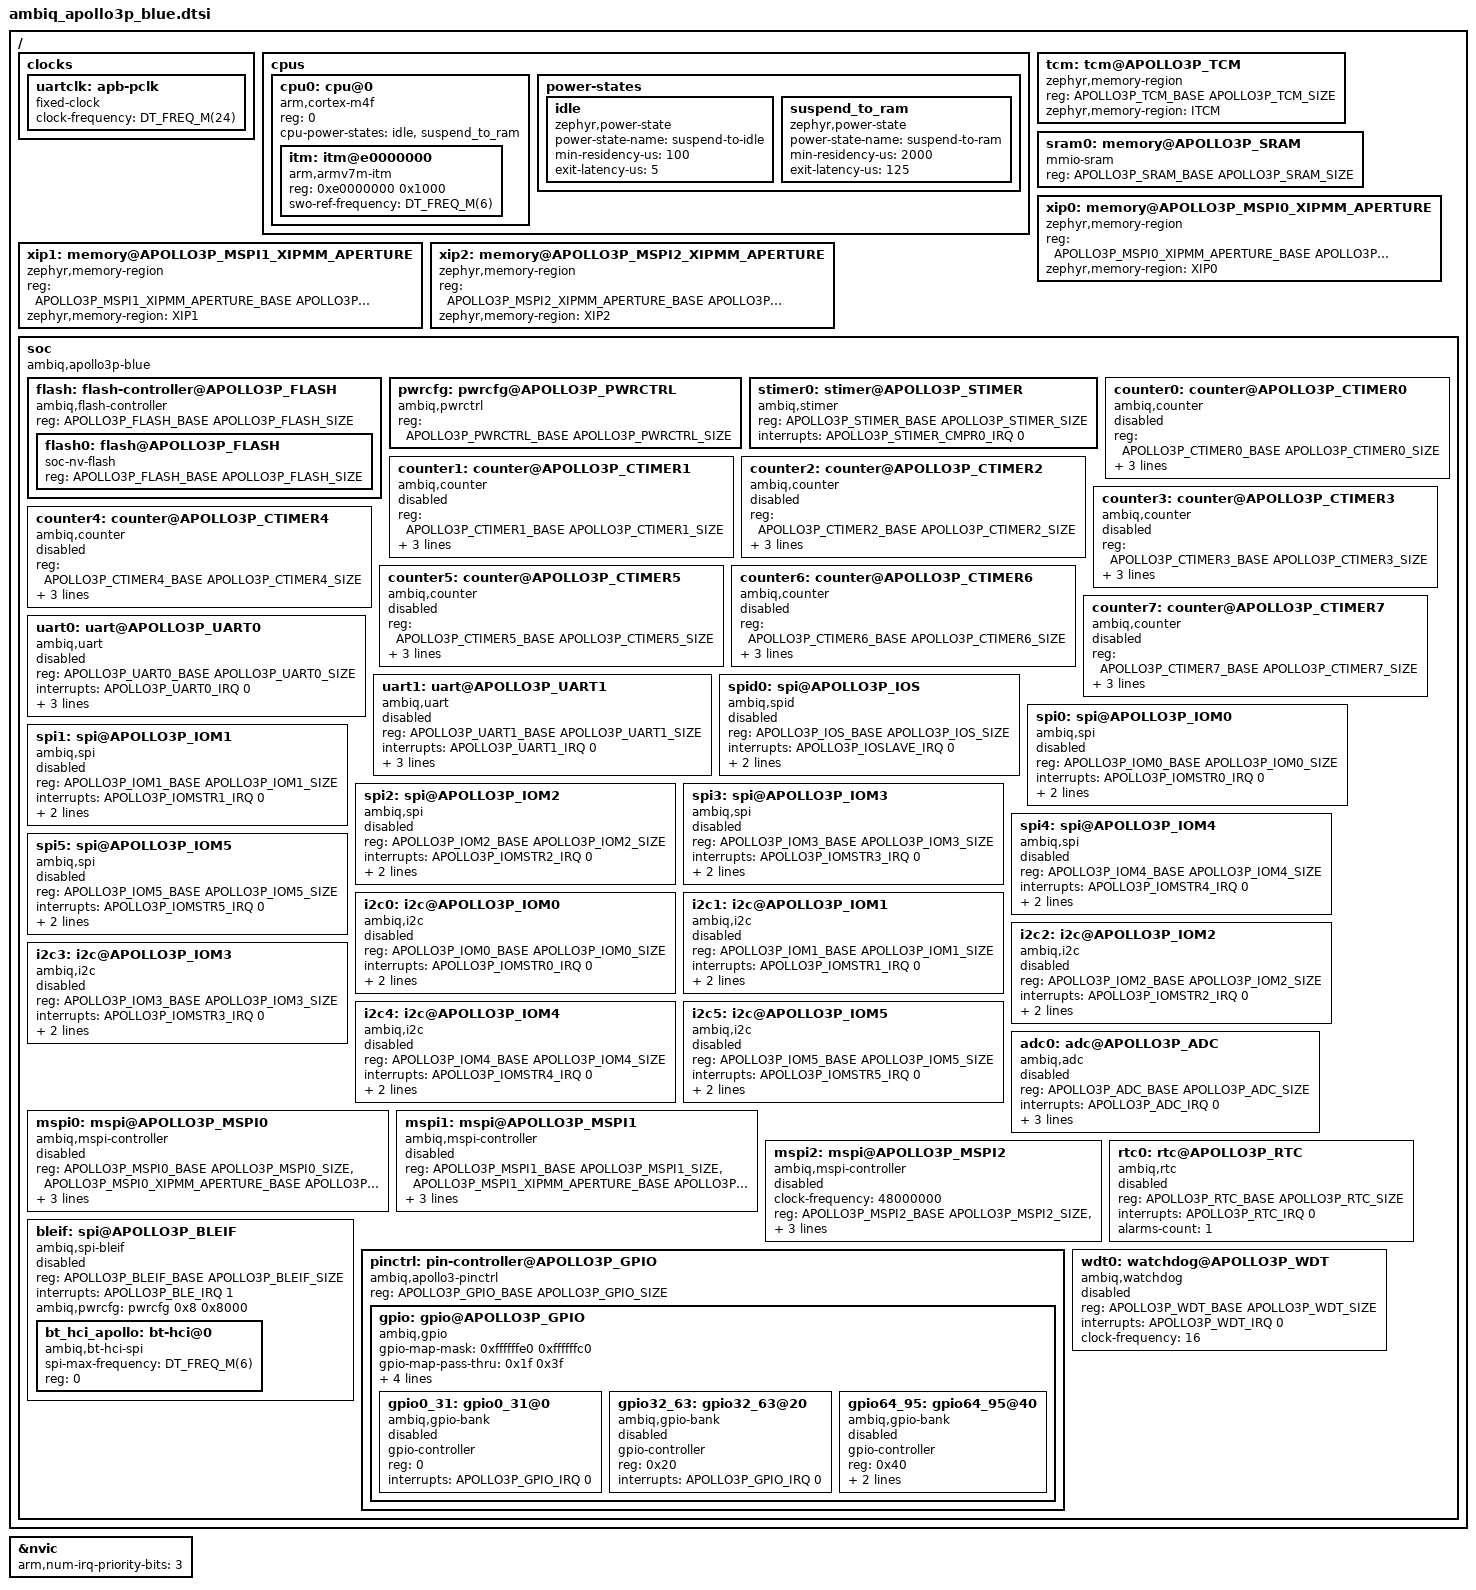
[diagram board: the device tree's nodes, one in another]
/* SPDX-License-Identifier: Apache-2.0 */

#include <arm/armv7-m.dtsi>
#include <mem.h>
#include <freq.h>
#include <apollo3p/am_apollo3p.h>
#include <zephyr/dt-bindings/adc/adc.h>
#include <zephyr/dt-bindings/i2c/i2c.h>
#include <zephyr/dt-bindings/gpio/gpio.h>

/ {
	clocks {
		uartclk: apb-pclk {
			compatible = "fixed-clock";
			clock-frequency = <DT_FREQ_M(24)>;
			#clock-cells = <0>;
		};
	};

	cpus {
		#address-cells = <1>;
		#size-cells = <0>;

		cpu0: cpu@0 {
			compatible = "arm,cortex-m4f";
			reg = <0>;
			cpu-power-states = <&idle &suspend_to_ram>;
			#address-cells = <1>;
			#size-cells = <1>;

			itm: itm@e0000000 {
				compatible = "arm,armv7m-itm";
				reg = <0xe0000000 0x1000>;
				swo-ref-frequency = <DT_FREQ_M(6)>;
			};
		};

		power-states {
			idle: idle {
				compatible = "zephyr,power-state";
				power-state-name = "suspend-to-idle";
				/* As Apollo3blueplus datasheet, run_to_sleep and sleep_to_run
				 * transition time are both lower than 1us, but considering
				 * the software overhead we set a bigger value.
				 */
				min-residency-us = <100>;
				exit-latency-us = <5>;
			};

			suspend_to_ram: suspend_to_ram {
				compatible = "zephyr,power-state";
				power-state-name = "suspend-to-ram";
				/* As Apollo3blueplus datasheet, run_to_deepsleep transition time
				 * is the software overhead 1us and deepsleep_to_run transition
				 * time is about 25us,but considering the software overhead,
				 * we set a bigger value.
				 */
				min-residency-us = <2000>;
				exit-latency-us = <125>;
			};
		};
	};

	/* TCM */
	tcm: tcm@APOLLO3P_TCM {
		compatible = "zephyr,memory-region";
		reg = <APOLLO3P_TCM_BASE APOLLO3P_TCM_SIZE>;
		zephyr,memory-region = "ITCM";
	};

	/* SRAM */
	sram0: memory@APOLLO3P_SRAM {
		compatible = "mmio-sram";
		reg = <APOLLO3P_SRAM_BASE APOLLO3P_SRAM_SIZE>;
	};

	xip0: memory@APOLLO3P_MSPI0_XIPMM_APERTURE {
		compatible = "zephyr,memory-region";
		reg = <APOLLO3P_MSPI0_XIPMM_APERTURE_BASE APOLLO3P_MSPI0_XIPMM_APERTURE_SIZE>;
		zephyr,memory-region = "XIP0";
	};

	xip1: memory@APOLLO3P_MSPI1_XIPMM_APERTURE {
		compatible = "zephyr,memory-region";
		reg = <APOLLO3P_MSPI1_XIPMM_APERTURE_BASE APOLLO3P_MSPI1_XIPMM_APERTURE_SIZE>;
		zephyr,memory-region = "XIP1";
	};

	xip2: memory@APOLLO3P_MSPI2_XIPMM_APERTURE {
		compatible = "zephyr,memory-region";
		reg = <APOLLO3P_MSPI2_XIPMM_APERTURE_BASE APOLLO3P_MSPI2_XIPMM_APERTURE_SIZE>;
		zephyr,memory-region = "XIP2";
	};

	soc {
		compatible = "ambiq,apollo3p-blue", "ambiq,apollo3x", "simple-bus";

		flash: flash-controller@APOLLO3P_FLASH {
			compatible = "ambiq,flash-controller";
			reg = <APOLLO3P_FLASH_BASE APOLLO3P_FLASH_SIZE>;

			#address-cells = <1>;
			#size-cells = <1>;

			/* Flash region */
			flash0: flash@APOLLO3P_FLASH {
				compatible = "soc-nv-flash";
				reg = <APOLLO3P_FLASH_BASE APOLLO3P_FLASH_SIZE>;
			};
		};

		pwrcfg: pwrcfg@APOLLO3P_PWRCTRL {
			compatible = "ambiq,pwrctrl";
			reg = <APOLLO3P_PWRCTRL_BASE APOLLO3P_PWRCTRL_SIZE>;
			#pwrcfg-cells = <2>;
		};

		stimer0: stimer@APOLLO3P_STIMER {
			compatible = "ambiq,stimer";
			reg = <APOLLO3P_STIMER_BASE APOLLO3P_STIMER_SIZE>;
			interrupts = <APOLLO3P_STIMER_CMPR0_IRQ 0>;
			status = "okay";
		};

		counter0: counter@APOLLO3P_CTIMER0 {
			compatible = "ambiq,counter";
			reg = <APOLLO3P_CTIMER0_BASE APOLLO3P_CTIMER0_SIZE>;
			interrupts = <APOLLO3P_CTIMER_IRQ 0>;
			clock-frequency = <DT_FREQ_M(3)>;
			clk-source = <2>;
			status = "disabled";
		};

		counter1: counter@APOLLO3P_CTIMER1 {
			compatible = "ambiq,counter";
			reg = <APOLLO3P_CTIMER1_BASE APOLLO3P_CTIMER1_SIZE>;
			interrupts = <APOLLO3P_CTIMER_IRQ 0>;
			clock-frequency = <DT_FREQ_M(3)>;
			clk-source = <2>;
			status = "disabled";
		};

		counter2: counter@APOLLO3P_CTIMER2 {
			compatible = "ambiq,counter";
			reg = <APOLLO3P_CTIMER2_BASE APOLLO3P_CTIMER2_SIZE>;
			interrupts = <APOLLO3P_CTIMER_IRQ 0>;
			clock-frequency = <DT_FREQ_M(3)>;
			clk-source = <2>;
			status = "disabled";
		};

		counter3: counter@APOLLO3P_CTIMER3 {
			compatible = "ambiq,counter";
			reg = <APOLLO3P_CTIMER3_BASE APOLLO3P_CTIMER3_SIZE>;
			interrupts = <APOLLO3P_CTIMER_IRQ 0>;
			clock-frequency = <DT_FREQ_M(3)>;
			clk-source = <2>;
			status = "disabled";
		};

		counter4: counter@APOLLO3P_CTIMER4 {
			compatible = "ambiq,counter";
			reg = <APOLLO3P_CTIMER4_BASE APOLLO3P_CTIMER4_SIZE>;
			interrupts = <APOLLO3P_CTIMER_IRQ 0>;
			clock-frequency = <DT_FREQ_M(3)>;
			clk-source = <2>;
			status = "disabled";
		};

		counter5: counter@APOLLO3P_CTIMER5 {
			compatible = "ambiq,counter";
			reg = <APOLLO3P_CTIMER5_BASE APOLLO3P_CTIMER5_SIZE>;
			interrupts = <APOLLO3P_CTIMER_IRQ 0>;
			clock-frequency = <DT_FREQ_M(3)>;
			clk-source = <2>;
			status = "disabled";
		};

		counter6: counter@APOLLO3P_CTIMER6 {
			compatible = "ambiq,counter";
			reg = <APOLLO3P_CTIMER6_BASE APOLLO3P_CTIMER6_SIZE>;
			interrupts = <APOLLO3P_CTIMER_IRQ 0>;
			clock-frequency = <DT_FREQ_M(3)>;
			clk-source = <2>;
			status = "disabled";
		};

		counter7: counter@APOLLO3P_CTIMER7 {
			compatible = "ambiq,counter";
			reg = <APOLLO3P_CTIMER7_BASE APOLLO3P_CTIMER7_SIZE>;
			interrupts = <APOLLO3P_CTIMER_IRQ 0>;
			clock-frequency = <DT_FREQ_M(3)>;
			clk-source = <2>;
			status = "disabled";
		};

		uart0: uart@APOLLO3P_UART0 {
			compatible = "ambiq,uart", "arm,pl011";
			reg = <APOLLO3P_UART0_BASE APOLLO3P_UART0_SIZE>;
			interrupts = <APOLLO3P_UART0_IRQ 0>;
			interrupt-names = "UART0";
			status = "disabled";
			clocks = <&uartclk>;
			ambiq,pwrcfg = <&pwrcfg 0x8 0x80>;
			zephyr,pm-device-runtime-auto;
		};

		uart1: uart@APOLLO3P_UART1 {
			compatible = "ambiq,uart", "arm,pl011";
			reg = <APOLLO3P_UART1_BASE APOLLO3P_UART1_SIZE>;
			interrupts = <APOLLO3P_UART1_IRQ 0>;
			interrupt-names = "UART1";
			status = "disabled";
			clocks = <&uartclk>;
			ambiq,pwrcfg = <&pwrcfg 0x8 0x100>;
			zephyr,pm-device-runtime-auto;
		};

		spid0: spi@APOLLO3P_IOS {
			compatible = "ambiq,spid";
			reg = <APOLLO3P_IOS_BASE APOLLO3P_IOS_SIZE>;
			#address-cells = <1>;
			#size-cells = <0>;
			interrupts = <APOLLO3P_IOSLAVE_IRQ 0>;
			status = "disabled";
			ambiq,pwrcfg = <&pwrcfg 0x8 0>;
			zephyr,pm-device-runtime-auto;
		};

		spi0: spi@APOLLO3P_IOM0 {
			compatible = "ambiq,spi";
			reg = <APOLLO3P_IOM0_BASE APOLLO3P_IOM0_SIZE>;
			#address-cells = <1>;
			#size-cells = <0>;
			interrupts = <APOLLO3P_IOMSTR0_IRQ 0>;
			status = "disabled";
			ambiq,pwrcfg = <&pwrcfg 0x8 0x2>;
			zephyr,pm-device-runtime-auto;
		};

		spi1: spi@APOLLO3P_IOM1 {
			compatible = "ambiq,spi";
			reg = <APOLLO3P_IOM1_BASE APOLLO3P_IOM1_SIZE>;
			#address-cells = <1>;
			#size-cells = <0>;
			interrupts = <APOLLO3P_IOMSTR1_IRQ 0>;
			status = "disabled";
			ambiq,pwrcfg = <&pwrcfg 0x8 0x4>;
			zephyr,pm-device-runtime-auto;
		};

		spi2: spi@APOLLO3P_IOM2 {
			compatible = "ambiq,spi";
			reg = <APOLLO3P_IOM2_BASE APOLLO3P_IOM2_SIZE>;
			#address-cells = <1>;
			#size-cells = <0>;
			interrupts = <APOLLO3P_IOMSTR2_IRQ 0>;
			status = "disabled";
			ambiq,pwrcfg = <&pwrcfg 0x8 0x8>;
			zephyr,pm-device-runtime-auto;
		};

		spi3: spi@APOLLO3P_IOM3 {
			compatible = "ambiq,spi";
			reg = <APOLLO3P_IOM3_BASE APOLLO3P_IOM3_SIZE>;
			#address-cells = <1>;
			#size-cells = <0>;
			interrupts = <APOLLO3P_IOMSTR3_IRQ 0>;
			status = "disabled";
			ambiq,pwrcfg = <&pwrcfg 0x8 0x10>;
			zephyr,pm-device-runtime-auto;
		};

		spi4: spi@APOLLO3P_IOM4 {
			compatible = "ambiq,spi";
			reg = <APOLLO3P_IOM4_BASE APOLLO3P_IOM4_SIZE>;
			#address-cells = <1>;
			#size-cells = <0>;
			interrupts = <APOLLO3P_IOMSTR4_IRQ 0>;
			status = "disabled";
			ambiq,pwrcfg = <&pwrcfg 0x8 0x20>;
			zephyr,pm-device-runtime-auto;
		};

		spi5: spi@APOLLO3P_IOM5 {
			compatible = "ambiq,spi";
			reg = <APOLLO3P_IOM5_BASE APOLLO3P_IOM5_SIZE>;
			#address-cells = <1>;
			#size-cells = <0>;
			interrupts = <APOLLO3P_IOMSTR5_IRQ 0>;
			status = "disabled";
			ambiq,pwrcfg = <&pwrcfg 0x8 0x40>;
			zephyr,pm-device-runtime-auto;
		};

		i2c0: i2c@APOLLO3P_IOM0 {
			compatible = "ambiq,i2c";
			reg = <APOLLO3P_IOM0_BASE APOLLO3P_IOM0_SIZE>;
			#address-cells = <1>;
			#size-cells = <0>;
			interrupts = <APOLLO3P_IOMSTR0_IRQ 0>;
			status = "disabled";
			ambiq,pwrcfg = <&pwrcfg 0x8 0x2>;
			zephyr,pm-device-runtime-auto;
		};

		i2c1: i2c@APOLLO3P_IOM1 {
			compatible = "ambiq,i2c";
			reg = <APOLLO3P_IOM1_BASE APOLLO3P_IOM1_SIZE>;
			#address-cells = <1>;
			#size-cells = <0>;
			interrupts = <APOLLO3P_IOMSTR1_IRQ 0>;
			status = "disabled";
			ambiq,pwrcfg = <&pwrcfg 0x8 0x4>;
			zephyr,pm-device-runtime-auto;
		};

		i2c2: i2c@APOLLO3P_IOM2 {
			compatible = "ambiq,i2c";
			reg = <APOLLO3P_IOM2_BASE APOLLO3P_IOM2_SIZE>;
			#address-cells = <1>;
			#size-cells = <0>;
			interrupts = <APOLLO3P_IOMSTR2_IRQ 0>;
			status = "disabled";
			ambiq,pwrcfg = <&pwrcfg 0x8 0x8>;
			zephyr,pm-device-runtime-auto;
		};

		i2c3: i2c@APOLLO3P_IOM3 {
			compatible = "ambiq,i2c";
			reg = <APOLLO3P_IOM3_BASE APOLLO3P_IOM3_SIZE>;
			#address-cells = <1>;
			#size-cells = <0>;
			interrupts = <APOLLO3P_IOMSTR3_IRQ 0>;
			status = "disabled";
			ambiq,pwrcfg = <&pwrcfg 0x8 0x10>;
			zephyr,pm-device-runtime-auto;
		};

		i2c4: i2c@APOLLO3P_IOM4 {
			compatible = "ambiq,i2c";
			reg = <APOLLO3P_IOM4_BASE APOLLO3P_IOM4_SIZE>;
			#address-cells = <1>;
			#size-cells = <0>;
			interrupts = <APOLLO3P_IOMSTR4_IRQ 0>;
			status = "disabled";
			ambiq,pwrcfg = <&pwrcfg 0x8 0x20>;
			zephyr,pm-device-runtime-auto;
		};

		i2c5: i2c@APOLLO3P_IOM5 {
			compatible = "ambiq,i2c";
			reg = <APOLLO3P_IOM5_BASE APOLLO3P_IOM5_SIZE>;
			#address-cells = <1>;
			#size-cells = <0>;
			interrupts = <APOLLO3P_IOMSTR5_IRQ 0>;
			status = "disabled";
			ambiq,pwrcfg = <&pwrcfg 0x8 0x40>;
			zephyr,pm-device-runtime-auto;
		};

		adc0: adc@APOLLO3P_ADC {
			compatible = "ambiq,adc";
			reg = <APOLLO3P_ADC_BASE APOLLO3P_ADC_SIZE>;
			interrupts = <APOLLO3P_ADC_IRQ 0>;
			interrupt-names = "ADC";
			channel-count = <10>;
			internal-vref-mv = <1500>;
			status = "disabled";
			#io-channel-cells = <1>;
			ambiq,pwrcfg = <&pwrcfg 0x8 0x200>;
		};

		mspi0: mspi@APOLLO3P_MSPI0 {
			compatible = "ambiq,mspi-controller";
			reg = <APOLLO3P_MSPI0_BASE APOLLO3P_MSPI0_SIZE>,
			<APOLLO3P_MSPI0_XIPMM_APERTURE_BASE APOLLO3P_MSPI0_XIPMM_APERTURE_SIZE>;
			clock-frequency = <48000000>;
			interrupts = <APOLLO3P_MSPI0_IRQ 0>;
			#address-cells = <1>;
			#size-cells = <0>;
			status = "disabled";
			ambiq,pwrcfg = <&pwrcfg 0x8 0x800>;
		};

		mspi1: mspi@APOLLO3P_MSPI1 {
			compatible = "ambiq,mspi-controller";
			reg = <APOLLO3P_MSPI1_BASE APOLLO3P_MSPI1_SIZE>,
			<APOLLO3P_MSPI1_XIPMM_APERTURE_BASE APOLLO3P_MSPI1_XIPMM_APERTURE_SIZE>;
			clock-frequency = <48000000>;
			interrupts = <APOLLO3P_MSPI1_IRQ 0>;
			#address-cells = <1>;
			#size-cells = <0>;
			status = "disabled";
			ambiq,pwrcfg = <&pwrcfg 0x8 0x1000>;
		};

		mspi2: mspi@APOLLO3P_MSPI2 {
			compatible = "ambiq,mspi-controller";
			clock-frequency = <48000000>;
			reg = <APOLLO3P_MSPI2_BASE APOLLO3P_MSPI2_SIZE>,
			<APOLLO3P_MSPI2_XIPMM_APERTURE_BASE APOLLO3P_MSPI2_XIPMM_APERTURE_SIZE>;
			interrupts = <APOLLO3P_MSPI2_IRQ 0>;
			#address-cells = <1>;
			#size-cells = <0>;
			status = "disabled";
			ambiq,pwrcfg = <&pwrcfg 0x8 0x2000>;
		};

		rtc0: rtc@APOLLO3P_RTC {
			compatible = "ambiq,rtc";
			reg = <APOLLO3P_RTC_BASE APOLLO3P_RTC_SIZE>;
			interrupts = <APOLLO3P_RTC_IRQ 0>;
			alarms-count = <1>;
			status = "disabled";
		};

		bleif: spi@APOLLO3P_BLEIF {
			compatible = "ambiq,spi-bleif";
			reg = <APOLLO3P_BLEIF_BASE APOLLO3P_BLEIF_SIZE>;
			interrupts = <APOLLO3P_BLE_IRQ 1>;
			#address-cells = <1>;
			#size-cells = <0>;
			status = "disabled";
			ambiq,pwrcfg = <&pwrcfg 0x8 0x8000>;

			bt_hci_apollo: bt-hci@0 {
				compatible = "ambiq,bt-hci-spi";
				spi-max-frequency = <DT_FREQ_M(6)>;
				reg = <0>;
			};
		};

		pinctrl: pin-controller@APOLLO3P_GPIO {
			compatible = "ambiq,apollo3-pinctrl";
			reg = <APOLLO3P_GPIO_BASE APOLLO3P_GPIO_SIZE>;
			#address-cells = <1>;
			#size-cells = <0>;

			gpio: gpio@APOLLO3P_GPIO {
				compatible = "ambiq,gpio";
				gpio-map-mask = <0xffffffe0 0xffffffc0>;
				gpio-map-pass-thru = <0x1f 0x3f>;
				gpio-map = <
					0x00 0x0 &gpio0_31 0x0 0x0
					0x20 0x0 &gpio32_63 0x0 0x0
					0x40 0x0 &gpio64_95 0x0 0x0
				>;
				reg = <APOLLO3P_GPIO_BASE>;
				#gpio-cells = <2>;
				#address-cells = <1>;
				#size-cells = <0>;
				ranges;

				gpio0_31: gpio0_31@0 {
					compatible = "ambiq,gpio-bank";
					gpio-controller;
					#gpio-cells = <2>;
					reg = <0>;
					interrupts = <APOLLO3P_GPIO_IRQ 0>;
					status = "disabled";
				};

				gpio32_63: gpio32_63@20 {
					compatible = "ambiq,gpio-bank";
					gpio-controller;
					#gpio-cells = <2>;
					reg = <0x20>;
					interrupts = <APOLLO3P_GPIO_IRQ 0>;
					status = "disabled";
				};

				gpio64_95: gpio64_95@40 {
					compatible = "ambiq,gpio-bank";
					gpio-controller;
					#gpio-cells = <2>;
					reg = <0x40>;
					interrupts = <APOLLO3P_GPIO_IRQ 0>;
					status = "disabled";
					ngpios = <10>;
				};
			};
		};

		wdt0: watchdog@APOLLO3P_WDT {
			compatible = "ambiq,watchdog";
			reg = <APOLLO3P_WDT_BASE APOLLO3P_WDT_SIZE>;
			interrupts = <APOLLO3P_WDT_IRQ 0>;
			clock-frequency = <16>;
			status = "disabled";
		};
	};
};

&nvic {
	arm,num-irq-priority-bits = <3>;
};
